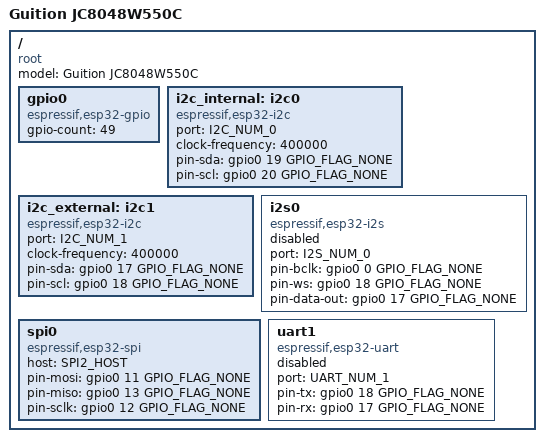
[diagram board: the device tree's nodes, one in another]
/dts-v1/;

#include <tactility/bindings/root.h>
#include <tactility/bindings/esp32_gpio.h>
#include <tactility/bindings/esp32_i2c.h>
#include <tactility/bindings/esp32_i2s.h>
#include <tactility/bindings/esp32_spi.h>
#include <tactility/bindings/esp32_uart.h>

/ {
	compatible = "root";
	model = "Guition JC8048W550C";

	gpio0 {
		compatible = "espressif,esp32-gpio";
		gpio-count = <49>;
	};

	i2c_internal: i2c0 {
		compatible = "espressif,esp32-i2c";
		port = <I2C_NUM_0>;
		clock-frequency = <400000>;
		pin-sda = <&gpio0 19 GPIO_FLAG_NONE>;
		pin-scl = <&gpio0 20 GPIO_FLAG_NONE>;
	};

	i2c_external: i2c1 {
		compatible = "espressif,esp32-i2c";
		port = <I2C_NUM_1>;
		clock-frequency = <400000>;
		pin-sda = <&gpio0 17 GPIO_FLAG_NONE>;
		pin-scl = <&gpio0 18 GPIO_FLAG_NONE>;
	};

	i2s0 {
		compatible = "espressif,esp32-i2s";
		status = "disabled";
		port = <I2S_NUM_0>;
		pin-bclk = <&gpio0 0 GPIO_FLAG_NONE>;
		pin-ws = <&gpio0 18 GPIO_FLAG_NONE>;
		pin-data-out = <&gpio0 17 GPIO_FLAG_NONE>;
	};

	spi0 {
		compatible = "espressif,esp32-spi";
		host = <SPI2_HOST>;
		pin-mosi = <&gpio0 11 GPIO_FLAG_NONE>;
		pin-miso = <&gpio0 13 GPIO_FLAG_NONE>;
		pin-sclk = <&gpio0 12 GPIO_FLAG_NONE>;
	};

	uart1 {
		compatible = "espressif,esp32-uart";
		status = "disabled";
		port = <UART_NUM_1>;
		pin-tx = <&gpio0 18 GPIO_FLAG_NONE>;
		pin-rx = <&gpio0 17 GPIO_FLAG_NONE>;
	};
};
